# PY32F403xx register map
Vendor: PUYA Co.Ltd; Series: ARMCM4; File version: 1.2
CPU: CM4 r0p1, little endian, MPU, FPU, 4 interrupt priority bits
Registers are 32-bit, read-write, reset 0x0 unless marked. A register's access mark holds for its fields unless they carry their own. Offsets are from the block's base; [hi:lo] are bit positions; {n}, {i} and the like mark numbered series.

## RCC
Base 0x40021000
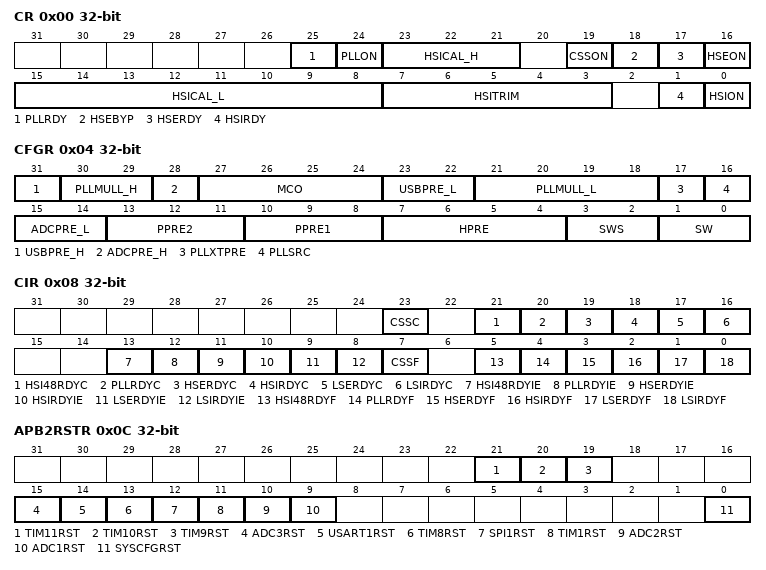
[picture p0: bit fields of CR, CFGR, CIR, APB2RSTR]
0x00 CR — clock control register
  [25] PLLRDY ro
  [24] PLLON — PLL enable
  [23:21] HSICAL_H ro — Internal high-speed clock calibration
  [19] CSSON
  [18] HSEBYP
  [17] HSERDY ro
  [16] HSEON
  [15:8] HSICAL_L ro — Internal high-speed clock calibration
  [7:3] HSITRIM — Internal high-speed clock trimming
    1=0; 2=1; 4=2; 8=3; 16=4
  [1] HSIRDY ro
  [0] HSION
0x04 CFGR — clock configuration register
  [31] USBPRE_H — desc USBPRE
  [30:29] PLLMULL_H — desc PLLMULL
  [28] ADCPRE_H — desc ADCPRE
  [27:24] MCO
  [23:22] USBPRE_L — desc USBPRE
  [21:18] PLLMULL_L — desc PLLMULL
  [17] PLLXTPRE
  [16] PLLSRC
  [15:14] ADCPRE_L — desc ADCPRE
  [13:11] PPRE2 — APB high-speed prescaler(APB2)
    1=0; 2=1; 4=2
  [10:8] PPRE1 — APB Low speed prescaler (APB1)
    0=DIV1 (HCLK not divided); 1=0; 2=1; 4=2; 4=DIV2 (HCLK divided by 2); 5=DIV4 (HCLK divided by 4); 6=DIV8 (HCLK divided by 8); 7=DIV16 (HCLK divided by 16)
  [7:4] HPRE
    0=DIV1 (SYSCLK not divided); 1=0; 2=1; 4=2; 8=3; 8=DIV2 (SYSCLK divided by 2); 9=DIV4 (SYSCLK divided by 4); 10=DIV8 (SYSCLK divided by 8); 11=DIV16 (SYSCLK divided by 16); 12=DIV64 (SYSCLK divided by 64); 13=DIV128 (SYSCLK divided by 128); 14=DIV256 (SYSCLK divided by 256); 15=DIV512 (SYSCLK divided by 512)
  [3:2] SWS
    0=HSI (HSI oscillator used as system clock); 1=0; 1=HSE (HSE oscillator used as system clock); 2=1; 2=PLL (PLL used as system clock)
  [1:0] SW
    0=HSI (HSI selected as system clock); 1=0; 1=HSE (HSE selected as system clock); 2=1; 2=PLL (PLL selected as system clock)
0x08 CIR — clock interrupt register
  [23] CSSC, [21] HSI48RDYC, [20] PLLRDYC, [19] HSERDYC, [18] HSIRDYC, [17] LSERDYC, [16] LSIRDYC, [13] HSI48RDYIE, [12] PLLRDYIE, [11] HSERDYIE, [10] HSIRDYIE, [9] LSERDYIE, [8] LSIRDYIE, [7] CSSF, [5] HSI48RDYF ro, [4] PLLRDYF ro, [3] HSERDYF ro, [2] HSIRDYF ro, [1] LSERDYF ro, [0] LSIRDYF ro
0x0C APB2RSTR — APB2 peripheral reset register
  [21] TIM11RST, [20] TIM10RST, [19] TIM9RST, [15] ADC3RST, [14] USART1RST, [13] TIM8RST, [12] SPI1RST, [11] TIM1RST, [10] ADC2RST, [9] ADC1RST, [0] SYSCFGRST
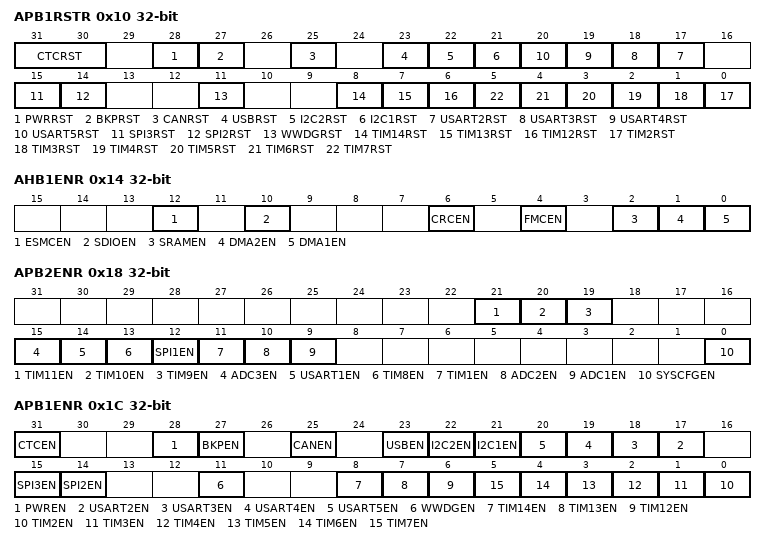
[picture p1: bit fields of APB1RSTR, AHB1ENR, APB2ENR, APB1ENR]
0x10 APB1RSTR — APB1 peripheral reset register
  [31:30] CTCRST, [28] PWRRST, [27] BKPRST, [25] CANRST, [23] USBRST, [22] I2C2RST, [21] I2C1RST, [n+15] USART{n}RST (n=2..5), [15] SPI3RST, [14] SPI2RST, [11] WWDGRST, [8] TIM14RST, [7] TIM13RST, [6] TIM12RST, [n-2] TIM{n}RST (n=2..7)
0x14 AHB1ENR — AHB1 peripheral clock register
  [12] ESMCEN, [10] SDIOEN, [6] CRCEN, [4] FMCEN, [2] SRAMEN, [1] DMA2EN, [0] DMA1EN
0x18 APB2ENR — APB2 peripheral clock enable register
  [21] TIM11EN, [20] TIM10EN, [19] TIM9EN, [15] ADC3EN, [14] USART1EN, [13] TIM8EN, [12] SPI1EN, [11] TIM1EN, [10] ADC2EN, [9] ADC1EN, [0] SYSCFGEN
0x1C APB1ENR — APB1 peripheral clock enable register
  [31] CTCEN, [28] PWREN, [27] BKPEN, [25] CANEN, [23] USBEN, [22] I2C2EN, [21] I2C1EN, [n+15] USART{n}EN (n=2..5), [15] SPI3EN, [14] SPI2EN, [11] WWDGEN, [8] TIM14EN, [7] TIM13EN, [6] TIM12EN, [n-2] TIM{n}EN (n=2..7)
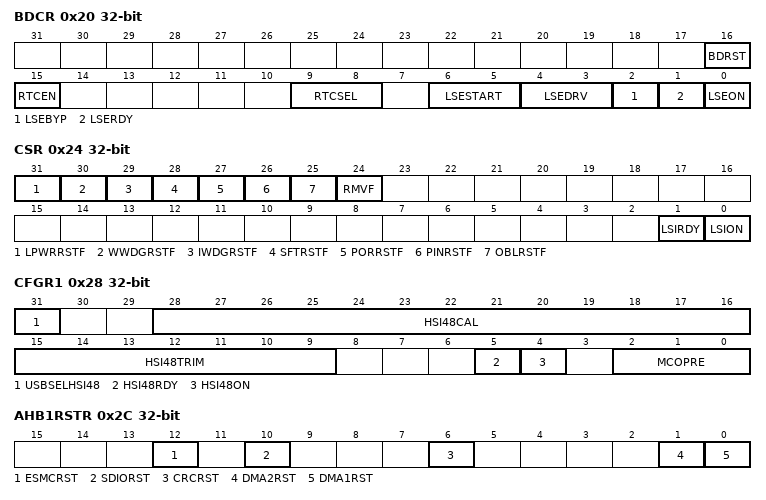
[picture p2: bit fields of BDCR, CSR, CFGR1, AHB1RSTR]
0x20 BDCR — Backup domain control register
  [16] BDRST
  [15] RTCEN
  [9:8] RTCSEL
    0=NOCLOCK; 1=0; 1=LSE (LSE oscillator clock used as RTC clock); 2=1; 2=LSI (LSI oscillator clock used as RTC clock); 3=HSE (HSE oscillator clock divided by 128 used as RTC clock)
  [6:5] LSESTART
  [4:3] LSEDRV
    1=0; 2=1
  [2] LSEBYP
  [1] LSERDY ro
  [0] LSEON
0x24 CSR — clock control & status register
  [31] LPWRRSTF ro, [30] WWDGRSTF ro, [29] IWDGRSTF ro, [28] SFTRSTF ro, [27] PORRSTF ro, [26] PINRSTF ro, [25] OBLRSTF ro, [24] RMVF, [1] LSIRDY ro, [0] LSION
0x28 CFGR1 — clock configuration register 1
  [31] USBSELHSI48
  [28:16] HSI48CAL ro
  [15:9] HSI48TRIM
    1=0; 2=1; 4=2; 8=3; 16=4; 32=5; 64=6
  [5] HSI48RDY ro
  [4] HSI48ON
  [2:0] MCOPRE
    1=0; 2=1; 4=2
0x2C AHB1RSTR — AHB1 peripheral reset register
  [12] ESMCRST, [10] SDIORST, [6] CRCRST, [1] DMA2RST, [0] DMA1RST
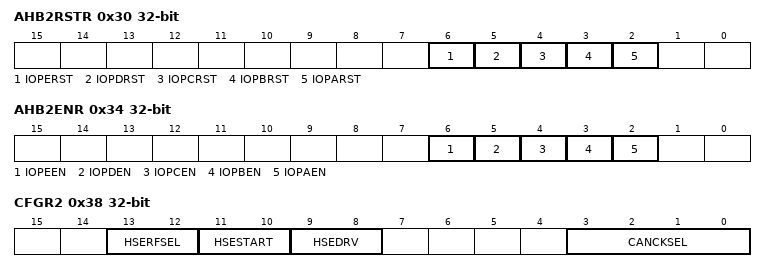
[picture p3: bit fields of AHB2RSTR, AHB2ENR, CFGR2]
0x30 AHB2RSTR — AHB2 peripheral reset register
  [6] IOPERST, [5] IOPDRST, [4] IOPCRST, [3] IOPBRST, [2] IOPARST
0x34 AHB2ENR — AHB2 peripheral clock register
  [6] IOPEEN, [5] IOPDEN, [4] IOPCEN, [3] IOPBEN, [2] IOPAEN
0x38 CFGR2
  [13:12] HSERFSEL
  [11:10] HSESTART
  [9:8] HSEDRV
    1=0; 2=1
  [3:0] CANCKSEL
    1=0; 2=1; 4=2; 8=3
